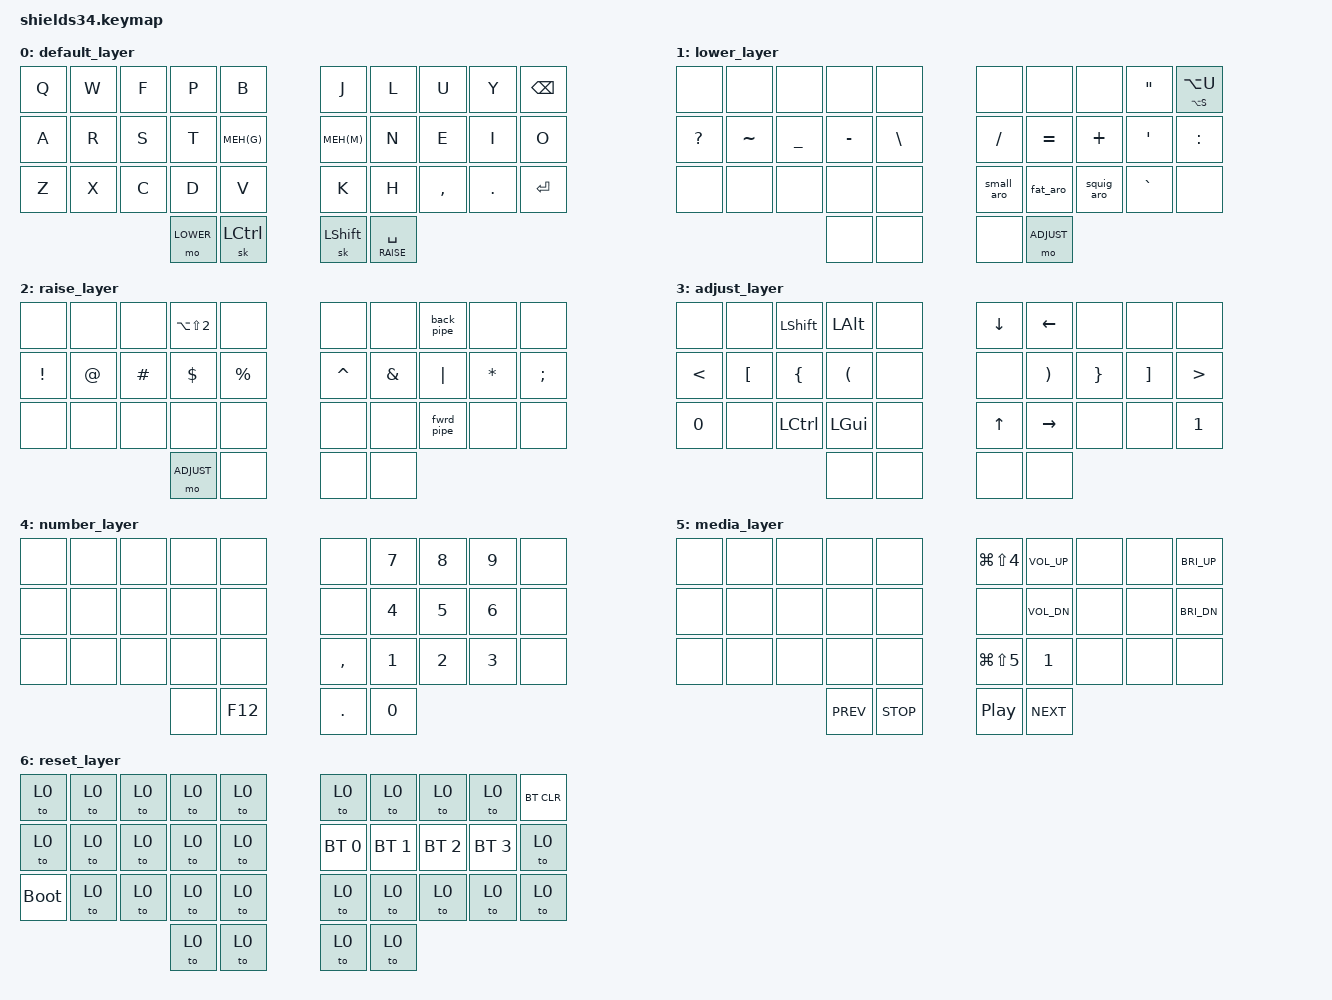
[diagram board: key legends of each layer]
// Copyright (c) 2022 The ZMK Contributors
// SPDX-License-Identifier: MIT

#include <behaviors.dtsi>
#include <dt-bindings/zmk/keys.h>
#include <dt-bindings/zmk/bt.h>

// Layers
#define DEFAULT 0
#define LOWER   1
#define RAISE   2
#define ADJUST  3
#define NUMBER  4
#define MEDIA   5
#define RESET   6

// Helper Constants
#define MEH(kc) &hl LC(LS(LALT)) kc
#define SCREEN &kp LG(LS(N4))
#define RECORD &kp LG(LS(N5))
#define EURO &kp LA(LS(N2))
#define GERMAN &td LA(S) LA(U)
#define SPC_RAISE &lt RAISE SPACE
#define BT_0 &bt BT_SEL 0
#define BT_1 &bt BT_SEL 1
#define BT_2 &bt BT_SEL 2
#define BT_3 &bt BT_SEL 3

/ {
    macros {
        back_pipe: back_pipe {
            label = "ZM_back_pipe";
            compatible = "zmk,behavior-macro";
            #binding-cells = <0>;
            bindings
                = <&macro_tap &kp LT>
                , <&macro_tap &kp PIPE>
                ;
        };
        fwrd_pipe: fwrd_pipe {
            label = "ZM_forward_pipe";
            compatible = "zmk,behavior-macro";
            #binding-cells = <0>;
            bindings
                = <&macro_tap &kp PIPE>
                , <&macro_tap &kp GT>
                ;
        };
        back_aro: back_aro {
            label = "ZM_back_arrow";
            compatible = "zmk,behavior-macro";
            #binding-cells = <0>;
            bindings
                = <&macro_tap &kp LT>
                , <&macro_tap &kp MINUS>
                ;
        };
        small_aro: small_aro {
            label = "ZM_small_arrow";
            compatible = "zmk,behavior-macro";
            #binding-cells = <0>;
            bindings
                = <&macro_tap &kp MINUS>
                , <&macro_tap &kp GT>
                ;
        };
        squig_aro: squig_aro {
            label = "ZM_squiggly_arrow";
            compatible = "zmk,behavior-macro";
            #binding-cells = <0>;
            bindings
                = <&macro_tap &kp TILDE>
                , <&macro_tap &kp GT>
                ;
        };
        fat_aro: fat_aro {
            label = "ZM_fat_arrow";
            compatible = "zmk,behavior-macro";
            #binding-cells = <0>;
            bindings
                = <&macro_tap &kp EQUAL>
                , <&macro_tap &kp GT>
                ;
        };
        js_equal: js_equal {
            label = "ZM_js_equal";
            compatible = "zmk,behavior-macro";
            #binding-cells = <0>;
            bindings
                = <&macro_tap &kp EQUAL>
                , <&macro_tap &kp EQUAL>
                , <&macro_tap &kp EQUAL>
                ;
        };
    };
    combos {
        compatible = "zmk,combos";
        combo_esc {
            timeout-ms = <50>;
            key-positions = <1 2>;
            bindings = <&kp ESC>;
        };
        combo_alt {
            timeout-ms = <50>;
            key-positions = <7 8>;
            bindings = <&sk LALT>;
        };
        combo_num {
            timeout-ms = <50>;
            key-positions = <11 12>;
            bindings = <&mo NUMBER>;
        };
        combo_tab {
            timeout-ms = <50>;
            key-positions = <21 22>;
            bindings = <&kp TAB>;
        };
        combo_gui {
            timeout-ms = <50>;
            key-positions = <27 28>;
            bindings = <&sk LGUI>;
        };
        combo_reset {
            timeout-ms = <50>;
            key-positions = <20 29>;
            layers = <3>;
            bindings = <&to RESET>;
        };
        combo_media {
            timeout-ms = <50>;
            key-positions = <2 3>;
            bindings = <&to MEDIA>;
        };
    };
    behaviors {
        hl: hold_layer {
            compatible = "zmk,behavior-hold-tap";
            label = "HOLD_LAYER";
            #binding-cells = <2>;
            tapping-term-ms = <300>;
            quick_tap_ms = <0>;
            flavor = "tap-preferred";
            bindings = <&kp>, <&kp>;
        };
        td: tapdance {
            compatible = "zmk,behavior-hold-tap";
            label = "TAPDANCE";
            #binding-cells = <2>;
            tapping-term-ms = <200>;
            quick_tap_ms = <0>;
            flavor = "tap-preferred";
            bindings = <&kp>, <&kp>;
        };
    };

    keymap {
        compatible = "zmk,keymap";
        default_layer {
            bindings = <
        //╭──────────┬──────────┬──────────┬──────────┬──────────╮  ╭──────────┬──────────┬──────────┬──────────┬──────────╮
        //│  Q       │  W    (ESC) F   (MEDIA)  P       │  B       │  │  J       │  L       │  U    (ALT) Y       │          │
            &kp Q      &kp W      &kp F      &kp P      &kp B         &kp J      &kp L      &kp U      &kp Y      &kp BSPC
        //├──────────┼──────────┼──────────┼──────────┼──────────┤  ├──────────┼──────────┼──────────┼──────────┼──────────┤
        //│  A       │  R  (NUMBER) S      │  T       │  G   MEH │  │  M   MEH │  N       │  E       │  I       │  O       │
            &kp A      &kp R      &kp S      &kp T      MEH(G)        MEH(M)     &kp N      &kp E      &kp I      &kp O
        //├──────────┼──────────┼──────────┼──────────┼──────────┤  ├──────────┼──────────┼──────────┼──────────┼──────────┤
        //│  Z       │  X    (TAB) C       │  D       │  V       │  │  K       │  H       │  ,    (GUI) .       │  ENTER   │
            &kp Z      &kp X      &kp C      &kp D      &kp V         &kp K      &kp H      &kp COMMA  &kp DOT    &kp ENTER
        //╰──────────┴──────────┴──────────┼──────────┼──────────┤  ├──────────┼──────────┼──────────┴──────────┴──────────╯
        //                                 │ LOWER    │ OSM CTLR      OSM SHIFT│SPC(RAISE)│
                                             &mo LOWER  &sk LCTRL    &sk LSHIFT  SPC_RAISE
        //                                 ╰──────────┴──────────╯  ╰──────────┴──────────╯
            >;
        };

        lower_layer {
            bindings = <
        //╭──────────┬──────────┬──────────┬──────────┬──────────╮  ╭──────────┬──────────┬──────────┬──────────┬──────────╮
        //│          │          │          │          │          │  │          │          │          │  "       │ Umlaut/ß │
            &none      &none      &none      &none      &none         &none      &none      &none      &kp DQT    GERMAN 
        //├──────────┼──────────┼──────────┼──────────┼──────────┤  ├──────────┼──────────┼──────────┼──────────┼──────────┤
        //│  ?       │  ~       │  _       │  -       │  \       │  │  /       │  =       │  +       │  '       │  :       │
            &kp QMARK  &kp TILDE  &kp UNDER  &kp MINUS  &kp BSLH      &kp FSLH   &kp EQUAL  &kp PLUS   &kp SQT    &kp COLON
        //├──────────┼──────────┼──────────┼──────────┼──────────┤  ├──────────┼──────────┼──────────┼──────────┼──────────┤
        //│          │          │          │          │          │  │  ->      │  =>      │  ~>      │  `       │          │
            &none      &none      &none      &none      &none         &small_aro &fat_aro   &squig_aro &kp GRAVE  &none 
        //╰──────────┴──────────┴──────────┼──────────┼──────────┤  ├──────────┼──────────┼──────────┴──────────┴──────────╯
        //                                 │          │          │  │          │ (ADJUST) │
                                             &none      &none         &none      &mo ADJUST
        //                                 ╰──────────┴──────────╯  ╰──────────┴──────────╯
            >;
        };

        raise_layer {
            bindings = <
        //╭──────────┬──────────┬──────────┬──────────┬──────────╮  ╭──────────┬──────────┬───────────┬─────────┬──────────╮
        //│          │          │          │  €       │          │  │          │          │  <|       │         │          │
            &none      &none      &none      EURO       &none         &none      &none      &back_pipe  &none     &none 
        //├──────────┼──────────┼──────────┼──────────┼──────────┤  ├──────────┼──────────┼───────────┼─────────┼──────────┤
        //│  !       │  @       │  #       │  $       │  %       │  │  ^       │  &       │  |        │  *      │  ;       │
            &kp EXCL   &kp AT     &kp HASH   &kp DLLR   &kp PRCNT     &kp CARET  &kp AMPS   &kp PIPE    &kp STAR  &kp SEMI
        //├──────────┼──────────┼──────────┼──────────┼──────────┤  ├──────────┼──────────┼───────────┼─────────┼──────────┤
        //│          │          │          │          │          │  │          │          │  |>       │         │          │
            &none      &none      &none      &none      &none         &none      &none      &fwrd_pipe  &none     &none 
        //╰──────────┴──────────┴──────────┼──────────┼──────────┤  ├──────────┼──────────┼───────────┴─────────┴──────────╯
        //                                 │ (ADJUST) │          │  │          │          │
                                            &mo ADJUST  &none         &none      &none
        //                                 ╰──────────┴──────────╯  ╰──────────┴──────────╯
            >;
        };

        adjust_layer {
            bindings = <
        //╭──────────┬──────────┬──────────┬──────────┬──────────╮  ╭──────────┬──────────┬──────────┬──────────┬──────────╮
        //│          │          │          │          │          │  │  DOWN    │  LEFT    │          │          │          │
            &none      &none     &kp LSHFT &kp LEFT_ALT &none         &kp DOWN   &kp LEFT   &none      &none      &none 
        //├──────────┼──────────┼──────────┼──────────┼──────────┤  ├──────────┼──────────┼──────────┼──────────┼──────────┤
        //│  <       │  [       │  {       │  (       │          │  │          │  )       │  }       │  ]       │  >       │
            &kp LT     &kp LBKT   &kp LBRC   &kp LPAR   &none         &none      &kp RPAR   &kp RBRC   &kp RBKT   &kp GT
        //├──────────┼──────────┼──────────┼──────────┼──────────┤  ├──────────┼──────────┼──────────┼──────────┼──────────┤
        //│  (RESET) │          │          │          │          │  │  UP      │  RIGHT   │          │          │  (RESET) │
            &kp N0     &none      &kp LCTRL &kp LEFT_GUI &none        &kp UP     &kp RIGHT  &none      &none      &kp N1
        //╰──────────┴──────────┴──────────┼──────────┼──────────┤  ├──────────┼──────────┼──────────┴──────────┴──────────╯
        //                                 │          │          │  │          │          │
                                             &none      &none         &none      &none 
        //                                 ╰──────────┴──────────╯  ╰──────────┴──────────╯
            >;
        };

        number_layer {
            bindings = < 
        //╭──────────┬──────────┬──────────┬──────────┬──────────╮  ╭──────────┬──────────┬──────────┬──────────┬──────────╮
        //│          │          │          │          │          │  │          │  7       │  8       │  9       │          │
            &none      &none      &none      &none      &none         &none      &kp N7     &kp N8     &kp N9     &none 
        //├──────────┼──────────┼──────────┼──────────┼──────────┤  ├──────────┼──────────┼──────────┼──────────┼──────────┤
        //│          │          │          │          │          │  │          │  4       │  5       │  6       │          │
            &none      &none      &none      &none      &none         &none      &kp N4     &kp N5     &kp N6     &none 
        //├──────────┼──────────┼──────────┼──────────┼──────────┤  ├──────────┼──────────┼──────────┼──────────┼──────────┤
        //│          │          │          │          │          │  │  ,       │  1       │  2       │  3       │          │
            &none      &none      &none      &none      &none         &kp COMMA  &kp N1     &kp N2     &kp N3     &none
        //╰──────────┴──────────┴──────────┼──────────┼──────────┤  ├──────────┼──────────┼──────────┴──────────┴──────────╯
        //                                 │          │  F12     │  │  .       │  0       │
                                             &none      &kp F12       &kp DOT    &kp N0
        //                                 ╰──────────┴──────────╯  ╰──────────┴──────────╯
            >;
        };

        media_layer {
            bindings = <
        //╭──────────┬──────────┬──────────┬──────────┬──────────╮  ╭──────────┬──────────┬──────────┬──────────┬──────────╮
        //│          │          │          │          │          │  │  Screen  │  Louder  │          │          │ Brighter │
            &none      &none      &none      &none      &none         SCREEN   &kp C_VOL_UP &none      &none    &kp C_BRI_UP
        //├──────────┼──────────┼──────────┼──────────┼──────────┤  ├──────────┼──────────┼──────────┼──────────┼──────────┤
        //│          │          │          │          │          │  │          │  Quieter │          │          │ Dimmer   │
            &none      &none      &none      &none      &none         &none    &kp C_VOL_DN &none      &none    &kp C_BRI_DN
        //├──────────┼──────────┼──────────┼──────────┼──────────┤  ├──────────┼──────────┼──────────┼──────────┼──────────┤
        //│          │          │          │          │          │  │  Record  │  Mute    │          │          │          │
            &none      &none      &none      &none      &none         RECORD    &kp N1      &none      &none      &none
        //╰──────────┴──────────┴──────────┼──────────┼──────────┤  ├──────────┼──────────┼──────────┴──────────┴──────────╯
        //                                 │ Previous │  Stop    │  │  Play    │  Next    │
                                            &kp C_PREV &kp C_STOP    &kp C_PP  &kp C_NEXT
        //                                 ╰──────────┴──────────╯  ╰──────────┴──────────╯
            >;
        };

        reset_layer {
            bindings = <
        //╭──────────┬──────────┬──────────┬──────────┬──────────╮  ╭──────────┬──────────┬──────────┬──────────┬──────────╮
        //│          │          │          │          │          │  │          │          │          │          │ CLEAR BT │
            &to 0      &to 0      &to 0      &to 0      &to 0         &to 0      &to 0      &to 0      &to 0      &bt BT_CLR
        //├──────────┼──────────┼──────────┼──────────┼──────────┤  ├──────────┼──────────┼──────────┼──────────┼──────────┤
        //│          │          │          │          │          │  │PROFILE 0 │PROFILE 1 │PROFILE 2 │PROFILE 3 │          │
            &to 0      &to 0      &to 0      &to 0      &to 0         BT_0       BT_1       BT_2       BT_3       &to 0
        //├──────────┼──────────┼──────────┼──────────┼──────────┤  ├──────────┼──────────┼──────────┼──────────┼──────────┤
        //│BOOTLOADER│          │          │          │          │  │          │          │          │          │          │
           &bootloader &to 0      &to 0      &to 0      &to 0         &to 0      &to 0      &to 0      &to 0      &to 0
        //╰──────────┴──────────┴──────────┼──────────┼──────────┤  ├──────────┼──────────┼──────────┴──────────┴──────────╯
        //                                 │          │          │  │          │          │
                                             &to 0      &to 0          &to 0     &to 0
        //                                 ╰──────────┴──────────╯  ╰──────────┴──────────╯
            >;
        };

    };
};
